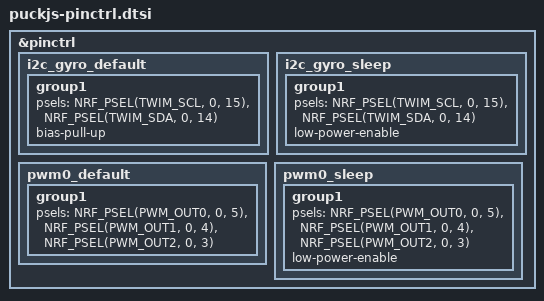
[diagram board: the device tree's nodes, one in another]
/*
 * Copyright (c) 2025 Martin Pietryka
 *
 * SPDX-License-Identifier: Apache-2.0
 */

&pinctrl {
	i2c_gyro_default: i2c_gyro_default {
		group1 {
			psels = <NRF_PSEL(TWIM_SCL, 0, 15)>,
				<NRF_PSEL(TWIM_SDA, 0, 14)>;
			bias-pull-up;
		};
	};

	i2c_gyro_sleep: i2c_gyro_sleep {
		group1 {
			psels = <NRF_PSEL(TWIM_SCL, 0, 15)>,
				<NRF_PSEL(TWIM_SDA, 0, 14)>;
			low-power-enable;
		};
	};

	pwm0_default: pwm0_default {
		group1 {
			psels = <NRF_PSEL(PWM_OUT0, 0, 5)>,	// LED_R
				<NRF_PSEL(PWM_OUT1, 0, 4)>,	// LED_G
				<NRF_PSEL(PWM_OUT2, 0, 3)>;	// LED_B
		};
	};

	pwm0_sleep: pwm0_sleep {
		group1 {
			psels = <NRF_PSEL(PWM_OUT0, 0, 5)>,	// LED_R
				<NRF_PSEL(PWM_OUT1, 0, 4)>,	// LED_G
				<NRF_PSEL(PWM_OUT2, 0, 3)>;	// LED_B
			low-power-enable;
		};
	};
};
